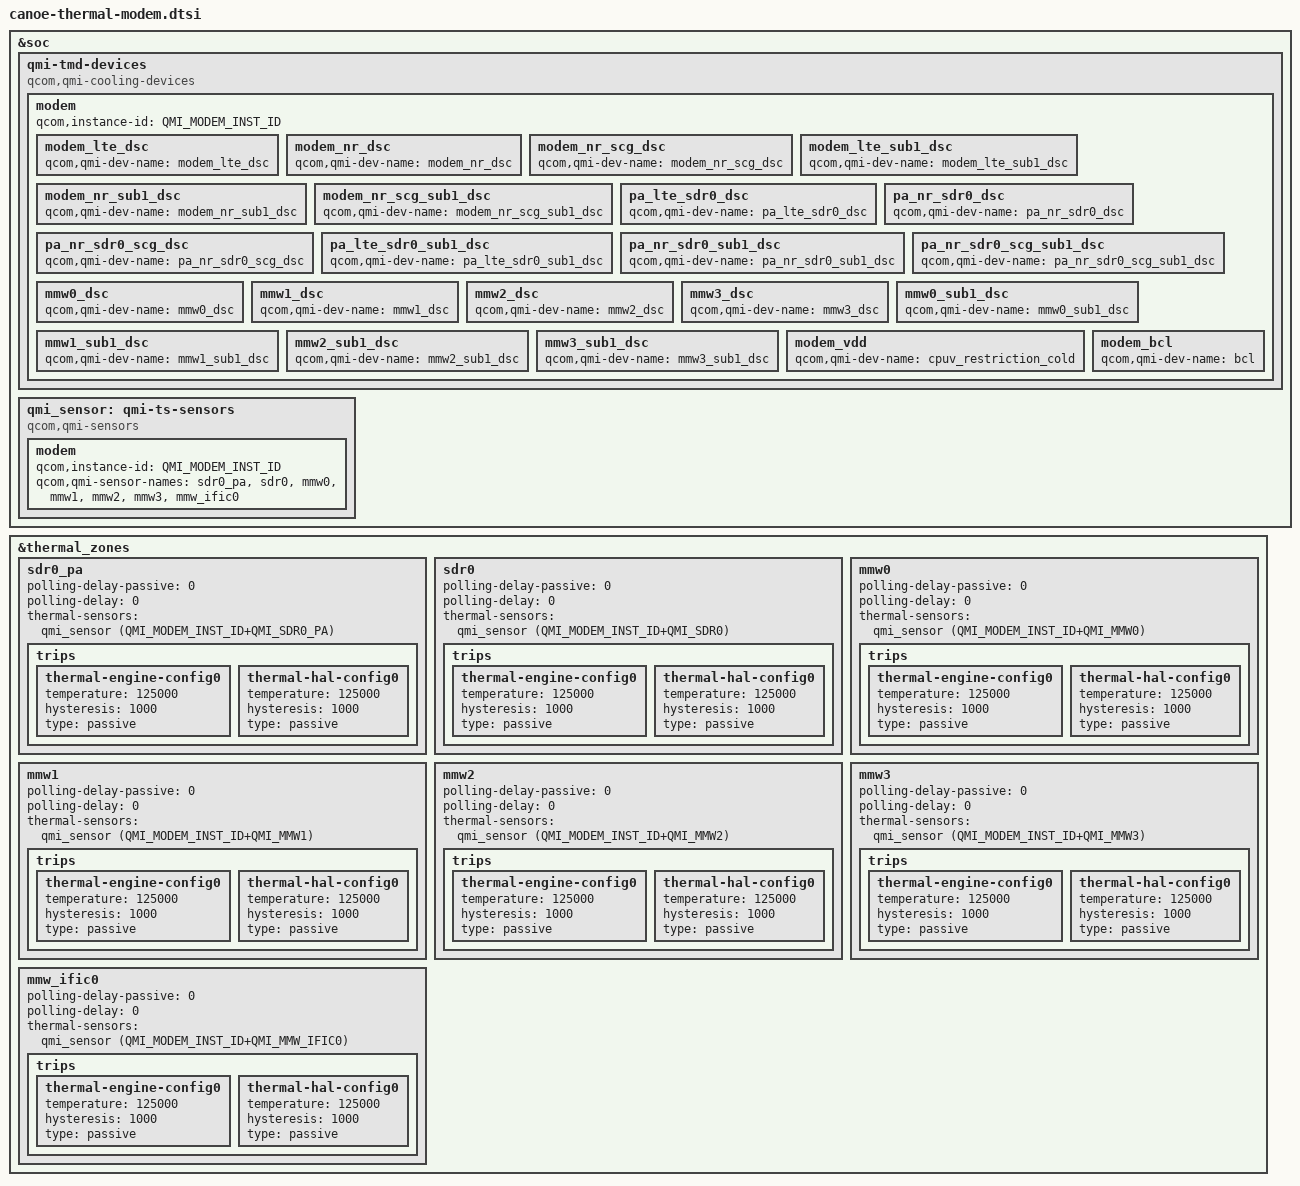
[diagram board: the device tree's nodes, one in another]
// SPDX-License-Identifier: BSD-3-Clause
/*
 * Copyright (c) 2024 Qualcomm Innovation Center, Inc. All rights reserved.
 */

#include <dt-bindings/thermal/thermal_qti.h>

&soc {
	qmi-tmd-devices {
		compatible = "qcom,qmi-cooling-devices";

		modem {
			qcom,instance-id = <QMI_MODEM_INST_ID>;

			modem_lte_dsc: modem_lte_dsc {
				qcom,qmi-dev-name = "modem_lte_dsc";
				#cooling-cells = <2>;
			};

			modem_nr_dsc: modem_nr_dsc {
				qcom,qmi-dev-name = "modem_nr_dsc";
				#cooling-cells = <2>;
			};

			modem_nr_scg_dsc: modem_nr_scg_dsc {
				qcom,qmi-dev-name = "modem_nr_scg_dsc";
				#cooling-cells = <2>;
			};

			modem_lte_sub1_dsc: modem_lte_sub1_dsc {
				qcom,qmi-dev-name = "modem_lte_sub1_dsc";
				#cooling-cells = <2>;
			};

			modem_nr_sub1_dsc: modem_nr_sub1_dsc {
				qcom,qmi-dev-name = "modem_nr_sub1_dsc";
				#cooling-cells = <2>;
			};

			modem_nr_scg_sub1_dsc: modem_nr_scg_sub1_dsc {
				qcom,qmi-dev-name = "modem_nr_scg_sub1_dsc";
				#cooling-cells = <2>;
			};

			pa_lte_sdr0_dsc: pa_lte_sdr0_dsc {
				qcom,qmi-dev-name = "pa_lte_sdr0_dsc";
				#cooling-cells = <2>;
			};

			pa_nr_sdr0_dsc: pa_nr_sdr0_dsc {
				qcom,qmi-dev-name = "pa_nr_sdr0_dsc";
				#cooling-cells = <2>;
			};

			pa_nr_sdr0_scg_dsc: pa_nr_sdr0_scg_dsc {
				qcom,qmi-dev-name = "pa_nr_sdr0_scg_dsc";
				#cooling-cells = <2>;
			};

			pa_lte_sdr0_sub1_dsc: pa_lte_sdr0_sub1_dsc {
				qcom,qmi-dev-name = "pa_lte_sdr0_sub1_dsc";
				#cooling-cells = <2>;
			};

			pa_nr_sdr0_sub1_dsc: pa_nr_sdr0_sub1_dsc {
				qcom,qmi-dev-name = "pa_nr_sdr0_sub1_dsc";
				#cooling-cells = <2>;
			};

			pa_nr_sdr0_scg_sub1_dsc: pa_nr_sdr0_scg_sub1_dsc {
				qcom,qmi-dev-name = "pa_nr_sdr0_scg_sub1_dsc";
				#cooling-cells = <2>;
			};

			mmw0_dsc: mmw0_dsc {
				qcom,qmi-dev-name = "mmw0_dsc";
				#cooling-cells = <2>;
			};

			mmw1_dsc: mmw1_dsc {
				qcom,qmi-dev-name = "mmw1_dsc";
				#cooling-cells = <2>;
			};

			mmw2_dsc: mmw2_dsc {
				qcom,qmi-dev-name = "mmw2_dsc";
				#cooling-cells = <2>;
			};

			mmw3_dsc: mmw3_dsc {
				qcom,qmi-dev-name = "mmw3_dsc";
				#cooling-cells = <2>;
			};

			mmw0_sub1_dsc: mmw0_sub1_dsc {
				qcom,qmi-dev-name = "mmw0_sub1_dsc";
				#cooling-cells = <2>;
			};

			mmw1_sub1_dsc: mmw1_sub1_dsc {
				qcom,qmi-dev-name = "mmw1_sub1_dsc";
				#cooling-cells = <2>;
			};

			mmw2_sub1_dsc: mmw2_sub1_dsc {
				qcom,qmi-dev-name = "mmw2_sub1_dsc";
				#cooling-cells = <2>;
			};

			mmw3_sub1_dsc: mmw3_sub1_dsc {
				qcom,qmi-dev-name = "mmw3_sub1_dsc";
				#cooling-cells = <2>;
			};

			modem_vdd: modem_vdd {
				qcom,qmi-dev-name = "cpuv_restriction_cold";
				#cooling-cells = <2>;
			};

			modem_bcl: modem_bcl {
				qcom,qmi-dev-name = "bcl";
				#cooling-cells = <2>;
			};
		};
	};

	qmi_sensor: qmi-ts-sensors {
		compatible = "qcom,qmi-sensors";
		#thermal-sensor-cells = <1>;

		modem {
			qcom,instance-id = <QMI_MODEM_INST_ID>;
			qcom,qmi-sensor-names = "sdr0_pa",
						"sdr0",
						"mmw0",
						"mmw1",
						"mmw2",
						"mmw3",
						"mmw_ific0";
		};
	};
};

&thermal_zones {
	sdr0_pa {
		polling-delay-passive = <0>;
		polling-delay = <0>;
		thermal-sensors = <&qmi_sensor
				(QMI_MODEM_INST_ID+QMI_SDR0_PA)>;
		trips {
			thermal-engine-config0 {
				temperature = <125000>;
				hysteresis = <1000>;
				type = "passive";
			};

			thermal-hal-config0 {
				temperature = <125000>;
				hysteresis = <1000>;
				type = "passive";
			};
		};
	};

	sdr0 {
		polling-delay-passive = <0>;
		polling-delay = <0>;
		thermal-sensors = <&qmi_sensor
				(QMI_MODEM_INST_ID+QMI_SDR0)>;
		trips {
			thermal-engine-config0 {
				temperature = <125000>;
				hysteresis = <1000>;
				type = "passive";
			};

			thermal-hal-config0 {
				temperature = <125000>;
				hysteresis = <1000>;
				type = "passive";
			};
		};
	};

	mmw0 {
		polling-delay-passive = <0>;
		polling-delay = <0>;
		thermal-sensors = <&qmi_sensor
				(QMI_MODEM_INST_ID+QMI_MMW0)>;
		trips {
			thermal-engine-config0 {
				temperature = <125000>;
				hysteresis = <1000>;
				type = "passive";
			};

			thermal-hal-config0 {
				temperature = <125000>;
				hysteresis = <1000>;
				type = "passive";
			};
		};
	};

	mmw1 {
		polling-delay-passive = <0>;
		polling-delay = <0>;
		thermal-sensors = <&qmi_sensor
				(QMI_MODEM_INST_ID+QMI_MMW1)>;
		trips {
			thermal-engine-config0 {
				temperature = <125000>;
				hysteresis = <1000>;
				type = "passive";
			};

			thermal-hal-config0 {
				temperature = <125000>;
				hysteresis = <1000>;
				type = "passive";
			};
		};
	};

	mmw2 {
		polling-delay-passive = <0>;
		polling-delay = <0>;
		thermal-sensors = <&qmi_sensor
				(QMI_MODEM_INST_ID+QMI_MMW2)>;
		trips {
			thermal-engine-config0 {
				temperature = <125000>;
				hysteresis = <1000>;
				type = "passive";
			};

			thermal-hal-config0 {
				temperature = <125000>;
				hysteresis = <1000>;
				type = "passive";
			};
		};
	};

	mmw3 {
		polling-delay-passive = <0>;
		polling-delay = <0>;
		thermal-sensors = <&qmi_sensor
				(QMI_MODEM_INST_ID+QMI_MMW3)>;
		trips {
			thermal-engine-config0 {
				temperature = <125000>;
				hysteresis = <1000>;
				type = "passive";
			};

			thermal-hal-config0 {
				temperature = <125000>;
				hysteresis = <1000>;
				type = "passive";
			};
		};
	};

	mmw_ific0 {
		polling-delay-passive = <0>;
		polling-delay = <0>;
		thermal-sensors = <&qmi_sensor
				(QMI_MODEM_INST_ID+QMI_MMW_IFIC0)>;
		trips {
			thermal-engine-config0 {
				temperature = <125000>;
				hysteresis = <1000>;
				type = "passive";
			};

			thermal-hal-config0 {
				temperature = <125000>;
				hysteresis = <1000>;
				type = "passive";
			};
		};
	};
};
